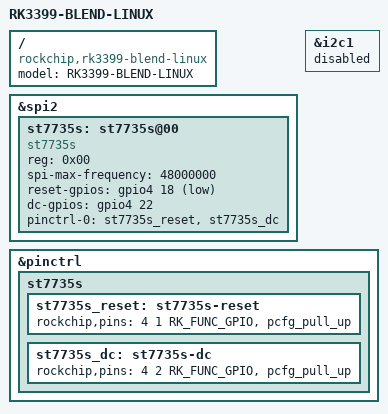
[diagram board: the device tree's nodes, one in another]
#include "rk3399-blend.dtsi"
#include "rk3399-linux.dtsi"
#define USE_RK_CONFIG 1
/ {
	model = "RK3399-BLEND-LINUX";
	compatible = "rockchip,rk3399-blend-linux", "rockchip,rk3399";	
};

&spi2{
	status = "okay";
	st7735s: st7735s@00{
		compatible = "st7735s";
		reg = <0x00>;
		spi-max-frequency = <48000000>;
#if USE_RK_CONFIG
		reset-gpios = <&gpio4 18 GPIO_ACTIVE_LOW>;/* GPIO4_C2 */	
		dc-gpios = <&gpio4 22 GPIO_ACTIVE_HIGH>;/* GPIO4_C6 */	//description
		pinctrl-names = "default";
		pinctrl-0 = <&st7735s_reset &st7735s_dc>;/*be careful of different api invoke in source files*/
#else 
		reset-gpios = <&gpio4 1 GPIO_ACTIVE_LOW>;/* GPIO4_A1 */
		dc-gpios = <&gpio4 2 GPIO_ACTIVE_HIGH>;/* GPIO4_A2 */
#endif
		};
};

&i2c1 {
	status = "disabled";/*dc & reset is assigned to i2c2 pins*/
};
#if USE_RK_CONFIG
&pinctrl {
	st7735s {
		st7735s_reset: st7735s-reset {
			rockchip,pins = <4 1 RK_FUNC_GPIO &pcfg_pull_up>;
		};
		st7735s_dc: st7735s-dc {
			rockchip,pins = <4 2 RK_FUNC_GPIO &pcfg_pull_up>;//configure
		};
	};
};
#endif
